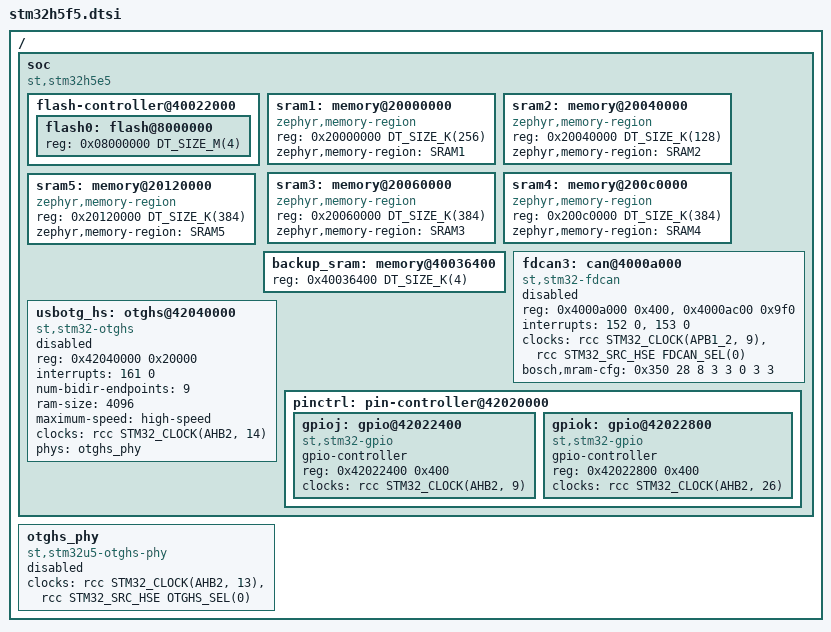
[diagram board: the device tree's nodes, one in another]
/*
 * Copyright (c) 2026 Arduino SRL
 *
 * SPDX-License-Identifier: Apache-2.0
 */
#include <st/h5/stm32h573.dtsi>
#include <zephyr/dt-bindings/clock/stm32u5_clock.h>

/ {
	soc {
		compatible = "st,stm32h5e5", "st,stm32h5f5", "st,stm32h5", "simple-bus";

		flash-controller@40022000 {
			flash0: flash@8000000 {
				reg = <0x08000000 DT_SIZE_M(4)>;
			};
		};

		/delete-node/ memory@20050000;

		sram1: memory@20000000 {
			compatible = "zephyr,memory-region", "mmio-sram";
			reg = <0x20000000 DT_SIZE_K(256)>;
			zephyr,memory-region = "SRAM1";
		};

		sram2: memory@20040000 {
			compatible = "zephyr,memory-region", "mmio-sram";
			reg = <0x20040000 DT_SIZE_K(128)>;
			zephyr,memory-region = "SRAM2";
		};

		sram3: memory@20060000 {
			compatible = "zephyr,memory-region", "mmio-sram";
			reg = <0x20060000 DT_SIZE_K(384)>;
			zephyr,memory-region = "SRAM3";
		};

		sram4: memory@200c0000 {
			compatible = "zephyr,memory-region", "mmio-sram";
			reg = <0x200c0000 DT_SIZE_K(384)>;
			zephyr,memory-region = "SRAM4";
		};

		sram5: memory@20120000 {
			compatible = "zephyr,memory-region", "mmio-sram";
			reg = <0x20120000 DT_SIZE_K(384)>;
			zephyr,memory-region = "SRAM5";
		};

		backup_sram: memory@40036400 {
			reg = <0x40036400 DT_SIZE_K(4)>;
		};

		fdcan3: can@4000a000 {
			compatible = "st,stm32-fdcan";
			reg = <0x4000a000 0x400>, <0x4000ac00 0x9f0>;
			reg-names = "m_can", "message_ram";
			interrupts = <152 0>, <153 0>;
			interrupt-names = "int0", "int1";
			/* common clock FDCAN 1 & 2 & 3*/
			clocks = <&rcc STM32_CLOCK(APB1_2, 9)>,
				 <&rcc STM32_SRC_HSE FDCAN_SEL(0)>;
			bosch,mram-cfg = <0x350 28 8 3 3 0 3 3>;
			status = "disabled";
		};

		usbotg_hs: otghs@42040000 {
			compatible = "st,stm32-otghs";
			reg = <0x42040000 0x20000>;
			interrupts = <161 0>;
			interrupt-names = "otghs";
			num-bidir-endpoints = <9>;
			ram-size = <4096>;
			maximum-speed = "high-speed";
			clocks = <&rcc STM32_CLOCK(AHB2, 14)>;
			phys = <&otghs_phy>;
			status = "disabled";
		};

		pinctrl: pin-controller@42020000 {
			gpioj: gpio@42022400 {
				compatible = "st,stm32-gpio";
				gpio-controller;
				#gpio-cells = <2>;
				reg = <0x42022400 0x400>;
				clocks = <&rcc STM32_CLOCK(AHB2, 9)>;
			};

			gpiok: gpio@42022800 {
				compatible = "st,stm32-gpio";
				gpio-controller;
				#gpio-cells = <2>;
				reg = <0x42022800 0x400>;
				clocks = <&rcc STM32_CLOCK(AHB2, 26)>;
			};
		};
	};

	otghs_phy: otghs_phy {
		compatible = "st,stm32u5-otghs-phy";
		clocks = <&rcc STM32_CLOCK(AHB2, 13)>,
			 <&rcc STM32_SRC_HSE OTGHS_SEL(0)>;
		#phy-cells = <0>;
		status = "disabled";
	};
};
